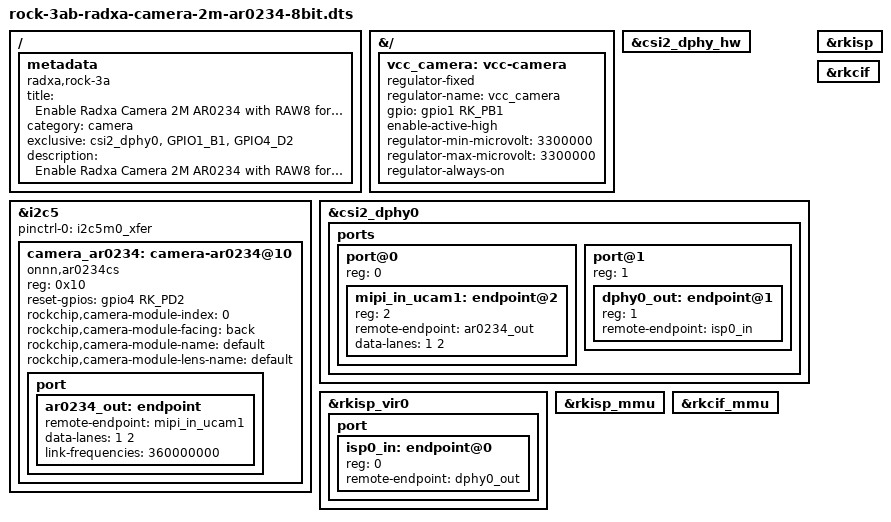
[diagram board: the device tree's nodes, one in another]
// ROCK 3A/3B Radxa Camera 2M AR0234
/dts-v1/;
/plugin/;

#include <dt-bindings/gpio/gpio.h>
#include <dt-bindings/pinctrl/rockchip.h>

/ {
	metadata {
		title = "Enable Radxa Camera 2M AR0234 with RAW8 format";
		compatible = "radxa,rock-3a", "radxa,rock-3b";
		category = "camera";
		exclusive = "csi2_dphy0", "GPIO1_B1", "GPIO4_D2";
		description = "Enable Radxa Camera 2M AR0234 with RAW8 format.";
	};
};

&{/} {
	vcc_camera: vcc-camera {
		status = "okay";
		compatible = "regulator-fixed";
		regulator-name = "vcc_camera";
		gpio = <&gpio1 RK_PB1 GPIO_ACTIVE_HIGH>;
		enable-active-high;
		regulator-min-microvolt = <3300000>;
		regulator-max-microvolt = <3300000>;
		regulator-always-on;
	};
};

&i2c5 {
	status = "okay";
	pinctrl-names = "default";
	pinctrl-0 = <&i2c5m0_xfer>;
	#address-cells = <1>;
	#size-cells = <0>;

	camera_ar0234: camera-ar0234@10 {
		status = "okay";
		compatible = "onnn,ar0234cs";
		reg = <0x10>;
		reset-gpios = <&gpio4 RK_PD2 GPIO_ACTIVE_HIGH>;
		rockchip,camera-module-index = <0>;
		rockchip,camera-module-facing = "back";
		rockchip,camera-module-name = "default";
		rockchip,camera-module-lens-name = "default";

		port {
			ar0234_out: endpoint {
				remote-endpoint = <&mipi_in_ucam1>;
				data-lanes = <1 2>;
				link-frequencies = /bits/ 64 <360000000>;
			};
		};
	};
};

&csi2_dphy_hw {
	status = "okay";
};

&csi2_dphy0 {
	status = "okay";

	ports {
		#address-cells = <1>;
		#size-cells = <0>;

		port@0 {
			reg = <0>;
			#address-cells = <1>;
			#size-cells = <0>;

			mipi_in_ucam1: endpoint@2 {
				reg = <2>;
				remote-endpoint = <&ar0234_out>;
				data-lanes = <1 2>;
			};
		};

		port@1 {
			reg = <1>;
			#address-cells = <1>;
			#size-cells = <0>;

			dphy0_out: endpoint@1 {
				reg = <1>;
				remote-endpoint = <&isp0_in>;
			};
		};
	};
};

&rkisp_vir0 {
	status = "okay";

	port {
		#address-cells = <1>;
		#size-cells = <0>;

		isp0_in: endpoint@0 {
			reg = <0>;
			remote-endpoint = <&dphy0_out>;
		};
	};
};

&rkisp {
	status = "okay";
};

&rkisp_mmu {
	status = "okay";
};

&rkcif_mmu {
	status = "okay";
};

&rkcif {
	status = "okay";
};
